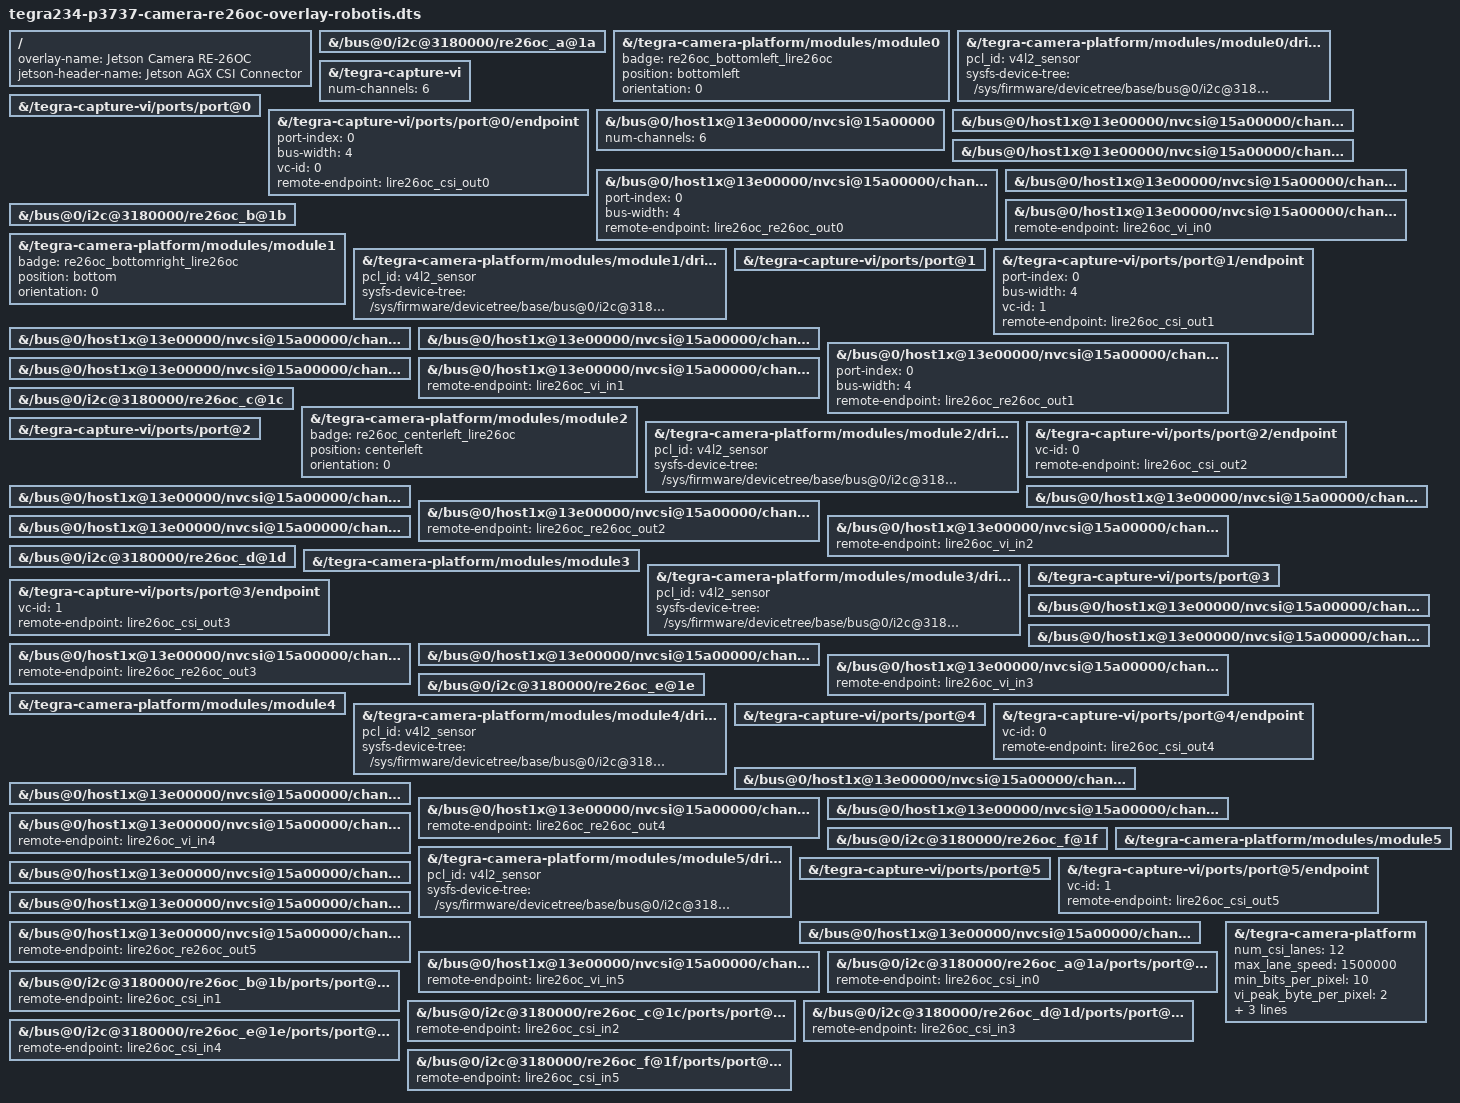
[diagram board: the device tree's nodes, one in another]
// SPDX-License-Identifier: GPL-2.0-only
/*
 * Jetson Device-tree overlay for Camera RE-26OC on t23x platforms
 *
 * Copyright (c) 2022 NVIDIA CORPORATION. All rights reserved.
 *
 */

 /dts-v1/;
 /plugin/;
 
 #include <dt-bindings/tegra234-p3737-0000+p3701-0000.h>
 
 / {
	 overlay-name = "Jetson Camera RE-26OC";
	 jetson-header-name = "Jetson AGX CSI Connector";
	 compatible = JETSON_COMPATIBLE;
 
	 /* re26oc module using ODM-DATA */
	 fragment@0 {
		 target-path = "/bus@0/i2c@3180000/re26oc_a@1a";
		 board_config {
			 sw-modules = "kernel";
		 };
		 __overlay__ {
			 status = "okay";
		 };
	 };
 
	 fragment@1 {
		 target-path = "/tegra-camera-platform/modules/module0";
		 board_config {
			 sw-modules = "kernel";
		 };
		 __overlay__ {
			 status = "okay";
			 badge = "re26oc_bottomleft_lire26oc";
			 position = "bottomleft";
			 orientation = "0";
		 };
	 };
	 
	 fragment@2 {
		 target-path = "/tegra-camera-platform/modules/module0/drivernode0";
		 board_config {
			 sw-modules = "kernel";
		 };
		 __overlay__ {
			 status = "okay";
			 pcl_id = "v4l2_sensor";
			 sysfs-device-tree = "/sys/firmware/devicetree/base/bus@0/i2c@3180000/re26oc_a@1a";
		 };
	 };
 
	 /* Enable VI ports */
	 fragment@4 {
		 target-path = "/tegra-capture-vi";
		 board_config {
			 sw-modules = "kernel";
		 };
		 __overlay__ {
			 status = "okay";
			 num-channels=<6>;
		 };
	 };
	 fragment@5 {
		 target-path = "/tegra-capture-vi/ports/port@0";
		 board_config {
			 sw-modules = "kernel";
		 };
		 __overlay__ {
			 status = "okay";
		 };
	 };
	 fragment@6 {
		 target-path = "/tegra-capture-vi/ports/port@0/endpoint";
		 board_config {
			 sw-modules = "kernel";
		 };
		 __overlay__ {
			 status = "okay";
			 port-index = <0>;
			 bus-width = <4>;
			 vc-id = <0>;
			 remote-endpoint = <&lire26oc_csi_out0>;
		 };
	 };
	 /* Enable CSI ports */
	 fragment@7 {
		 target-path = "/bus@0/host1x@13e00000/nvcsi@15a00000";
		 board_config {
			 sw-modules = "kernel";
		 };
		 __overlay__ {
			 num-channels=<6>;
		 };
	 };
	 fragment@8 {
		 target-path = "/bus@0/host1x@13e00000/nvcsi@15a00000/channel@0";
		 board_config {
			 sw-modules = "kernel";
		 };
		 __overlay__ {
			 status = "okay";
		 };
	 };
	 fragment@9 {
		 target-path = "/bus@0/host1x@13e00000/nvcsi@15a00000/channel@0/ports/port@0";
		 board_config {
			 sw-modules = "kernel";
		 };
		 __overlay__ {
			 status = "okay";
		 };
	 };
	 fragment@10 {
		 target-path = "/bus@0/host1x@13e00000/nvcsi@15a00000/channel@0/ports/port@0/endpoint@0";
		 board_config {
			 sw-modules = "kernel";
		 };
		 __overlay__ {
			 status = "okay";
			 port-index = <0>;
			 bus-width = <4>;
			 remote-endpoint = <&lire26oc_re26oc_out0>;
		 };
	 };
	 fragment@11 {
		 target-path = "/bus@0/host1x@13e00000/nvcsi@15a00000/channel@0/ports/port@1";
		 board_config {
			 sw-modules = "kernel";
		 };
		 __overlay__ {
			 status = "okay";
		 };
	 };
	 fragment@12 {
		 target-path = "/bus@0/host1x@13e00000/nvcsi@15a00000/channel@0/ports/port@1/endpoint@1";
		 board_config {
			 sw-modules = "kernel";
		 };
		 __overlay__ {
			 status = "okay";
			 remote-endpoint = <&lire26oc_vi_in0>;
		 };
	 };
 
	 fragment@28 {
		 target-path = "/bus@0/i2c@3180000/re26oc_b@1b";
		 board_config {
			 sw-modules = "kernel";
		 };
		 __overlay__ {
			 status = "okay";
		 };
	 };
	 fragment@29 {
		 target-path = "/tegra-camera-platform/modules/module1";
		 board_config {
			 sw-modules = "kernel";
		 };
		 __overlay__ {
			 status = "okay";
			 badge = "re26oc_bottomright_lire26oc";
			 position = "bottom";
			 orientation = "0";
		 };
	 };
	 fragment@30 {
		 target-path = "/tegra-camera-platform/modules/module1/drivernode0";
		 board_config {
			 sw-modules = "kernel";
		 };
		 __overlay__ {
			 status = "okay";
			 pcl_id = "v4l2_sensor";
			 sysfs-device-tree = "/sys/firmware/devicetree/base/bus@0/i2c@3180000/re26oc_b@1b";
		 };
	 };
 
	 fragment@31 {
		 target-path = "/tegra-capture-vi/ports/port@1";
		 board_config {
			 sw-modules = "kernel";
		 };
		 __overlay__ {
			 status = "okay";
		 };
	 };
	 fragment@32 {
		 target-path = "/tegra-capture-vi/ports/port@1/endpoint";
		 board_config {
			 sw-modules = "kernel";
		 };
		 __overlay__ {
			 status = "okay";
			 port-index = <0>;
			 bus-width = <4>;
			 vc-id = <1>;
			 remote-endpoint = <&lire26oc_csi_out1>;
		 };
	 };
 
	 fragment@33 {
		 target-path = "/bus@0/host1x@13e00000/nvcsi@15a00000/channel@1";
		 board_config {
			 sw-modules = "kernel";
		 };
		 __overlay__ {
			 status = "okay";
		 };
	 };
	 fragment@34 {
		 target-path = "/bus@0/host1x@13e00000/nvcsi@15a00000/channel@1/ports/port@0";
		 board_config {
			 sw-modules = "kernel";
		 };
		 __overlay__ {
			 status = "okay";
		 };
	 };
 
	 fragment@35 {
		 target-path = "/bus@0/host1x@13e00000/nvcsi@15a00000/channel@1/ports/port@0/endpoint@2";
		 board_config {
			 sw-modules = "kernel";
		 };
		 __overlay__ {
			 status = "okay";
			 port-index = <0>;
			 bus-width = <4>;
			 remote-endpoint = <&lire26oc_re26oc_out1>;
		 };
	 };
	 fragment@36 {
		 target-path = "/bus@0/host1x@13e00000/nvcsi@15a00000/channel@1/ports/port@1";
		 board_config {
			 sw-modules = "kernel";
		 };
		 __overlay__ {
			 status = "okay";
		 };
	 };
	 fragment@37 {
		 target-path = "/bus@0/host1x@13e00000/nvcsi@15a00000/channel@1/ports/port@1/endpoint@3";
		 board_config {
			 sw-modules = "kernel";
		 };
		 __overlay__ {
			 status = "okay";
			 remote-endpoint = <&lire26oc_vi_in1>;
		 };
	 };
 
	 fragment@48 {
		 target-path = "/bus@0/i2c@3180000/re26oc_c@1c";
		 board_config {
			 sw-modules = "kernel";
		 };
		 __overlay__ {
			 status = "okay";
		 };
	 };
	 fragment@49 {
		 target-path = "/tegra-camera-platform/modules/module2";
		 board_config {
			 sw-modules = "kernel";
		 };
		 __overlay__ {
			 status = "okay";
			 badge = "re26oc_centerleft_lire26oc";
			 position = "centerleft";
			 orientation = "0";
		 };
	 };
	 fragment@50 {
		 target-path = "/tegra-camera-platform/modules/module2/drivernode0";
		 board_config {
			 sw-modules = "kernel";
		 };
		 __overlay__ {
			 status = "okay";
			 pcl_id = "v4l2_sensor";
			 sysfs-device-tree = "/sys/firmware/devicetree/base/bus@0/i2c@3180000/re26oc_c@1c";
		 };
	 };
 
	 fragment@51 {
		 target-path = "/tegra-capture-vi/ports/port@2";
		 board_config {
			 sw-modules = "kernel";
		 };
		 __overlay__ {
			 status = "okay";
		 };
	 };
 
	 fragment@52 {
		 target-path = "/tegra-capture-vi/ports/port@2/endpoint";
		 board_config {
			 sw-modules = "kernel";
		 };
		 __overlay__ {
			 status = "okay";
			 vc-id = <0>;
			 remote-endpoint = <&lire26oc_csi_out2>;
		 };
	 };
	 
 
	 fragment@53 {
		 target-path = "/bus@0/host1x@13e00000/nvcsi@15a00000/channel@2";
		 board_config {
			 sw-modules = "kernel";
		 };
		 __overlay__ {
			 status = "okay";
		 };
	 };
	 fragment@54 {
		 target-path = "/bus@0/host1x@13e00000/nvcsi@15a00000/channel@2/ports/port@0";
		 board_config {
			 sw-modules = "kernel";
		 };
		 __overlay__ {
			 status = "okay";
		 };
	 };
 
	 fragment@55 {
		 target-path = "/bus@0/host1x@13e00000/nvcsi@15a00000/channel@2/ports/port@0/endpoint@4";
		 board_config {
			 sw-modules = "kernel";
		 };
		 __overlay__ {
			 status = "okay";
			 remote-endpoint = <&lire26oc_re26oc_out2>;
		 };
	 };
 
	 fragment@56 {
		 target-path = "/bus@0/host1x@13e00000/nvcsi@15a00000/channel@2/ports/port@1";
		 board_config {
			 sw-modules = "kernel";
		 };
		 __overlay__ {
			 status = "okay";
		 };
	 };
 
	 fragment@57 {
		 target-path = "/bus@0/host1x@13e00000/nvcsi@15a00000/channel@2/ports/port@1/endpoint@5";
		 board_config {
			 sw-modules = "kernel";
		 };
		 __overlay__ {
			 status = "okay";
			 remote-endpoint = <&lire26oc_vi_in2>;
		 };
	 };
 
 
	 fragment@60 {
		 target-path = "/bus@0/i2c@3180000/re26oc_d@1d";
		 board_config {
			 sw-modules = "kernel";
		 };
		 __overlay__ {
			 status = "okay";
		 };
	 };
	 fragment@61 {
		 target-path = "/tegra-camera-platform/modules/module3";
		 board_config {
			 sw-modules = "kernel";
		 };
		 __overlay__ {
			 status = "okay";
		 };
	 };
	 fragment@62 {
		 target-path = "/tegra-camera-platform/modules/module3/drivernode0";
		 board_config {
			 sw-modules = "kernel";
		 };
		 __overlay__ {
			 status = "okay";
			 pcl_id = "v4l2_sensor";
			 sysfs-device-tree = "/sys/firmware/devicetree/base/bus@0/i2c@3180000/re26oc_d@1d";
		 };
	 };
 
 
	 fragment@63 {
		 target-path = "/tegra-capture-vi/ports/port@3";
		 board_config {
			 sw-modules = "kernel";
		 };
		 __overlay__ {
			 status = "okay";
		 };
	 };
 
 
	 fragment@64 {
		 target-path = "/tegra-capture-vi/ports/port@3/endpoint";
		 board_config {
			 sw-modules = "kernel";
		 };
		 __overlay__ {
			 status = "okay";
			 vc-id = <1>;
			 remote-endpoint = <&lire26oc_csi_out3>;
		 };
	 };
 
	 fragment@65 {
		 target-path = "/bus@0/host1x@13e00000/nvcsi@15a00000/channel@3";
		 board_config {
			 sw-modules = "kernel";
		 };
		 __overlay__ {
			 status = "okay";
		 };
	 };
	 fragment@66 {
		 target-path = "/bus@0/host1x@13e00000/nvcsi@15a00000/channel@3/ports/port@0";
		 board_config {
			 sw-modules = "kernel";
		 };
		 __overlay__ {
			 status = "okay";
		 };
	 };
 
	 fragment@67 {
		 target-path = "/bus@0/host1x@13e00000/nvcsi@15a00000/channel@3/ports/port@0/endpoint@6";
		 board_config {
			 sw-modules = "kernel";
		 };
		 __overlay__ {
			 status = "okay";
			 remote-endpoint = <&lire26oc_re26oc_out3>;
		 };
	 };
 
	 fragment@68 {
		 target-path = "/bus@0/host1x@13e00000/nvcsi@15a00000/channel@3/ports/port@1";
		 board_config {
			 sw-modules = "kernel";
		 };
		 __overlay__ {
			 status = "okay";
		 };
	 };
	 fragment@69 {
		 target-path = "/bus@0/host1x@13e00000/nvcsi@15a00000/channel@3/ports/port@1/endpoint@7";
		 board_config {
			 sw-modules = "kernel";
		 };
		 __overlay__ {
			 status = "okay";
			 remote-endpoint = <&lire26oc_vi_in3>;
		 };
	 };
 
 
	 fragment@70 {
		 target-path = "/bus@0/i2c@3180000/re26oc_e@1e";
		 board_config {
			 sw-modules = "kernel";
		 };
		 __overlay__ {
			 status = "okay";
		 };
	 };
	 fragment@71 {
		 target-path = "/tegra-camera-platform/modules/module4";
		 board_config {
			 sw-modules = "kernel";
		 };
		 __overlay__ {
			 status = "okay";
		 };
	 };
	 fragment@72 {
		 target-path = "/tegra-camera-platform/modules/module4/drivernode0";
		 board_config {
			 sw-modules = "kernel";
		 };
		 __overlay__ {
			 status = "okay";
			 pcl_id = "v4l2_sensor";
			 sysfs-device-tree = "/sys/firmware/devicetree/base/bus@0/i2c@3180000/re26oc_e@1e";
		 };
	 };
 
	 fragment@73 {
		 target-path = "/tegra-capture-vi/ports/port@4";
		 board_config {
			 sw-modules = "kernel";
		 };
		 __overlay__ {
			 status = "okay";
		 };
	 };
 
 
	 fragment@74 {
		 target-path = "/tegra-capture-vi/ports/port@4/endpoint";
		 board_config {
			 sw-modules = "kernel";
		 };
		 __overlay__ {
			 status = "okay";
			 vc-id = <0>;
			 remote-endpoint = <&lire26oc_csi_out4>;
		 };
	 };
 
	 fragment@75 {
		 target-path = "/bus@0/host1x@13e00000/nvcsi@15a00000/channel@4";
		 board_config {
			 sw-modules = "kernel";
		 };
		 __overlay__ {
			 status = "okay";
		 };
	 };
	 fragment@76 {
		 target-path = "/bus@0/host1x@13e00000/nvcsi@15a00000/channel@4/ports/port@0";
		 board_config {
			 sw-modules = "kernel";
		 };
		 __overlay__ {
			 status = "okay";
		 };
	 };
 
	 fragment@77 {
		 target-path = "/bus@0/host1x@13e00000/nvcsi@15a00000/channel@4/ports/port@0/endpoint@8";
		 board_config {
			 sw-modules = "kernel";
		 };
		 __overlay__ {
			 status = "okay";
			 remote-endpoint = <&lire26oc_re26oc_out4>;
		 };
	 };
 
	 fragment@78 {
		 target-path = "/bus@0/host1x@13e00000/nvcsi@15a00000/channel@4/ports/port@1";
		 board_config {
			 sw-modules = "kernel";
		 };
		 __overlay__ {
			 status = "okay";
		 };
	 };
 
	 fragment@79 {
		 target-path = "/bus@0/host1x@13e00000/nvcsi@15a00000/channel@4/ports/port@1/endpoint@9";
		 board_config {
			 sw-modules = "kernel";
		 };
		 __overlay__ {
			 status = "okay";
			 remote-endpoint = <&lire26oc_vi_in4>;
		 };
	 };
 
 
	 fragment@80 {
		 target-path = "/bus@0/i2c@3180000/re26oc_f@1f";
		 board_config {
			 sw-modules = "kernel";
		 };
		 __overlay__ {
			 status = "okay";
		 };
	 };
	 fragment@81 {
		 target-path = "/tegra-camera-platform/modules/module5";
		 board_config {
			 sw-modules = "kernel";
		 };
		 __overlay__ {
			 status = "okay";
		 };
	 };
	 fragment@82 {
		 target-path = "/tegra-camera-platform/modules/module5/drivernode0";
		 board_config {
			 sw-modules = "kernel";
		 };
		 __overlay__ {
			 status = "okay";
			 pcl_id = "v4l2_sensor";
			 sysfs-device-tree = "/sys/firmware/devicetree/base/bus@0/i2c@3180000/re26oc_f@1f";
		 };
	 };
 
	 // Enable VI ports
	 fragment@83 {
		 target-path = "/tegra-capture-vi/ports/port@5";
		 board_config {
			 sw-modules = "kernel";
		 };
		 __overlay__ {
			 status = "okay";
		 };
	 };
 
 
 
	 fragment@84 {
		 target-path = "/tegra-capture-vi/ports/port@5/endpoint";
		 board_config {
			 sw-modules = "kernel";
		 };
		 __overlay__ {
			 status = "okay";
			 vc-id = <1>;
			 remote-endpoint = <&lire26oc_csi_out5>;
		 };
	 };
	 // Enable CSI ports
 
	 fragment@85 {
		 target-path = "/bus@0/host1x@13e00000/nvcsi@15a00000/channel@5";
		 board_config {
			 sw-modules = "kernel";
		 };
		 __overlay__ {
			 status = "okay";
		 };
	 };
	 fragment@86 {
		 target-path = "/bus@0/host1x@13e00000/nvcsi@15a00000/channel@5/ports/port@0";
		 board_config {
			 sw-modules = "kernel";
		 };
		 __overlay__ {
			 status = "okay";
		 };
	 };
 
	 fragment@87 {
		 target-path = "/bus@0/host1x@13e00000/nvcsi@15a00000/channel@5/ports/port@0/endpoint@10";
		 board_config {
			 sw-modules = "kernel";
		 };
		 __overlay__ {
			 status = "okay";
			 remote-endpoint = <&lire26oc_re26oc_out5>;
		 };
	 };
 
	 fragment@88 {
		 target-path = "/bus@0/host1x@13e00000/nvcsi@15a00000/channel@5/ports/port@1";
		 board_config {
			 sw-modules = "kernel";
		 };
		 __overlay__ {
			 status = "okay";
		 };
	 };
	 fragment@89 {
		 //// target = <&lire26oc_csi_out5>;
		 target-path = "/bus@0/host1x@13e00000/nvcsi@15a00000/channel@5/ports/port@1/endpoint@11";
		 board_config {
			 sw-modules = "kernel";
		 };
		 __overlay__ {
			 status = "okay";
			 remote-endpoint = <&lire26oc_vi_in5>;
		 };
	 };
 
 
	 /* lire26oc_re26oc_out ports */
	 fragment@100 {
		 target-path = "/bus@0/i2c@3180000/re26oc_a@1a/ports/port@0/endpoint";
		 board_config {
			 sw-modules = "kernel";
		 };
		 __overlay__ {
			 status = "okay";
			 remote-endpoint = <&lire26oc_csi_in0>;
		 };
	 };
 
	 fragment@101 {
		 target-path = "/bus@0/i2c@3180000/re26oc_b@1b/ports/port@0/endpoint";
		 board_config {
			 sw-modules = "kernel";
		 };
		 __overlay__ {
			 status = "okay";
			 remote-endpoint = <&lire26oc_csi_in1>;
		 };
	 };
 
	 fragment@102 {
		 target-path = "/bus@0/i2c@3180000/re26oc_c@1c/ports/port@0/endpoint";
		 board_config {
			 sw-modules = "kernel";
		 };
		 __overlay__ {
			 status = "okay";
			 remote-endpoint = <&lire26oc_csi_in2>;
		 };
	 };
 
	 fragment@103 {
		 target-path = "/bus@0/i2c@3180000/re26oc_d@1d/ports/port@0/endpoint";
		 board_config {
			 sw-modules = "kernel";
		 };
		 __overlay__ {
			 status = "okay";
			 remote-endpoint = <&lire26oc_csi_in3>;
		 };
	 };
 
	 fragment@104 {
		 target-path = "/bus@0/i2c@3180000/re26oc_e@1e/ports/port@0/endpoint";
		 board_config {
			 sw-modules = "kernel";
		 };
		 __overlay__ {
			 status = "okay";
			 remote-endpoint = <&lire26oc_csi_in4>;
		 };
	 };
 
	 fragment@105 {
		 target-path = "/bus@0/i2c@3180000/re26oc_f@1f/ports/port@0/endpoint";
		 board_config {
			 sw-modules = "kernel";
		 };
		 __overlay__ {
			 status = "okay";
			 remote-endpoint = <&lire26oc_csi_in5>;
		 };
	 };
 
	 /* tegra-camera-platform settings */
	 fragment@110 {
		 target-path = "/tegra-camera-platform";
		 board_config {
			 sw-modules = "kernel";
		 };
		 __overlay__ {
			 num_csi_lanes = <12>;
			 max_lane_speed = <1500000>;
			 min_bits_per_pixel = <10>;
			 vi_peak_byte_per_pixel = <2>;
			 vi_bw_margin_pct = <25>;
			 isp_peak_byte_per_pixel = <5>;
			 isp_bw_margin_pct = <25>;
		 };
	 };
 
 };
 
